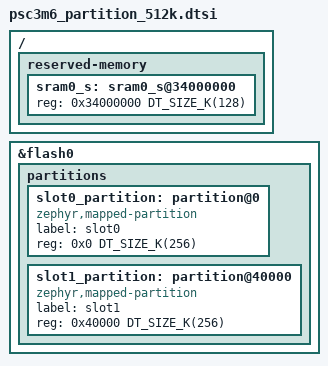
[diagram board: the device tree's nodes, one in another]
/*
 * SPDX-FileCopyrightText: Copyright (c) 2026 Infineon Technologies AG,
 * SPDX-FileCopyrightText: or an affiliate of Infineon Technologies AG. All rights reserved.
 *
 * SPDX-License-Identifier: Apache-2.0
 */

/*
 * Two 256 KB mcuboot slots, 512 KB total. Valid only for the 512 KB-flash
 * PSC3M6 MPNs (psc3m6ges3a*q1). The 256 KB MPNs (psc3m6fds2a*q1) must use
 * psc3m6_partition_256k.dtsi instead.
 */
/ {
	reserved-memory {
		#address-cells = <1>;
		#size-cells = <1>;
		ranges;

		sram0_s: sram0_s@34000000 {
			/* Secure image SRAM */
			reg = <0x34000000 DT_SIZE_K(128)>;
		};
	};
};

&flash0 {
	partitions {
		ranges;
		#address-cells = <1>;
		#size-cells = <1>;

		slot0_partition: partition@0 {
			compatible = "zephyr,mapped-partition";
			label = "slot0";
			reg = <0x0 DT_SIZE_K(256)>;
		};

		slot1_partition: partition@40000 {
			compatible = "zephyr,mapped-partition";
			label = "slot1";
			reg = <0x40000 DT_SIZE_K(256)>;
		};
	};
};
